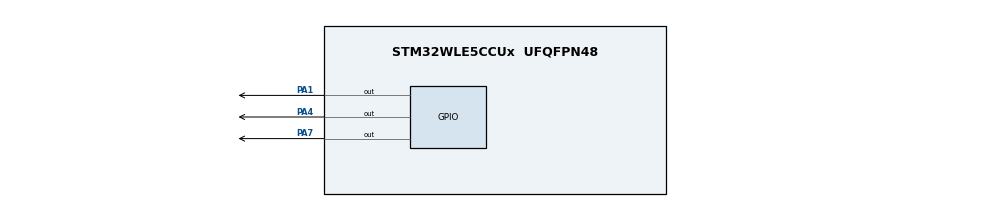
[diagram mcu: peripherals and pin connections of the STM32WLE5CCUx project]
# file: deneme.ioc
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ADC.Channel-0\#ChannelRegularConversion=ADC_CHANNEL_TEMPSENSOR
ADC.ContinuousConvMode=ENABLE
ADC.EnableRegularConversion=ENABLE
ADC.NbrOfConversion=1
ADC.NbrOfConversionFlag=1
ADC.Rank-0\#ChannelRegularConversion=1
ADC.SamplingTime-0\#ChannelRegularConversion=ADC_SAMPLINGTIME_COMMON_1
ADC.SamplingTimeCommon1=ADC_SAMPLETIME_79CYCLES_5
ADC.SelectedChannel=ADC_CHANNEL_TEMPSENSOR
Mcu.Family=STM32WL
Mcu.Name=STM32WLE5CCUx
Mcu.Package=UFQFPN48
NVIC.PriorityGroup=NVIC_PRIORITYGROUP_4
PA1.Signal=GPIO_Output
PA4.Signal=GPIO_Output
PA7.Signal=GPIO_Output
ProjectManager.HeapSize=0x200
ProjectManager.StackSize=0x400
ProjectManager.TargetToolchain=STM32CubeIDE
RCC.HSE_VALUE=8000000
RCC.HSI_VALUE=16000000
RCC.LSE_VALUE=32768
RCC.VCOOutputFreq_Value=32000000
VP_ADC_TempSens_Input.Mode=IN-TempSens
board=custom

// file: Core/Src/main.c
/* USER CODE BEGIN Header */
/**
  ******************************************************************************
  * @file           : main.c
  * @brief          : Main program body
  ******************************************************************************
  * @attention
  *
  * Copyright (c) 2022 STMicroelectronics.
  * All rights reserved.
  *
  * This software is licensed under terms that can be found in the LICENSE file
  * in the root directory of this software component.
  * If no LICENSE file comes with this software, it is provided AS-IS.
  *
  ******************************************************************************
  */
/* USER CODE END Header */
#include "main.h"

ADC_HandleTypeDef hadc;

/* USER CODE BEGIN PV */

uint16_t readValue;
float tCelsius;
float tFahrenheit;

/* USER CODE END PV */

void SystemClock_Config(void);
static void MX_GPIO_Init(void);
static void MX_ADC_Init(void);

int main(void)
{

  /* MCU Configuration--------------------------------------------------------*/

  /* Reset of all peripherals, Initializes the Flash interface and the Systick. */
  HAL_Init();

  /* Configure the system clock */
  SystemClock_Config();

  /* Initialize all configured peripherals */
  MX_GPIO_Init();
  MX_ADC_Init();
  /* USER CODE BEGIN 2 */
  HAL_ADC_Start(&hadc);

  /* USER CODE END 2 */

  /* Infinite loop */
  /* USER CODE BEGIN WHILE */
  while (1)
    {
      HAL_ADC_PollForConversion(&hadc,1000);
      readValue = HAL_ADC_GetValue(&hadc);
      tCelsius = 357.558 - 0.187364 * readValue;
      tFahrenheit = 675.6 - 0.337255 * readValue;
      if (readValue > 1740)
      {
        HAL_GPIO_WritePin(GPIOA, GPIO_PIN_7, 1);
        HAL_GPIO_WritePin(GPIOA, GPIO_PIN_4, 0);
        HAL_GPIO_WritePin(GPIOA, GPIO_PIN_1, 0);
      }
      else if (readValue > 1720 )
      {
        HAL_GPIO_WritePin(GPIOA, GPIO_PIN_7, 0);
        HAL_GPIO_WritePin(GPIOA, GPIO_PIN_4, 1);

        HAL_GPIO_WritePin(GPIOA, GPIO_PIN_1, 0);
      }
      else
      {
        HAL_GPIO_WritePin(GPIOA, GPIO_PIN_7, 0);
        HAL_GPIO_WritePin(GPIOA, GPIO_PIN_4, 0);
        HAL_GPIO_WritePin(GPIOA, GPIO_PIN_1, 1);
      }
      HAL_Delay(100);
    }
  /* USER CODE END 3 */
}

void SystemClock_Config(void)
{
  RCC_OscInitTypeDef RCC_OscInitStruct = {0};
  RCC_ClkInitTypeDef RCC_ClkInitStruct = {0};

  /** Configure the main internal regulator output voltage
  */
  __HAL_PWR_VOLTAGESCALING_CONFIG(PWR_REGULATOR_VOLTAGE_SCALE2);

  /** Initializes the CPU, AHB and APB buses clocks
  */
  RCC_OscInitStruct.OscillatorType = RCC_OSCILLATORTYPE_MSI;
  RCC_OscInitStruct.MSIState = RCC_MSI_ON;
  RCC_OscInitStruct.MSICalibrationValue = RCC_MSICALIBRATION_DEFAULT;
  RCC_OscInitStruct.MSIClockRange = RCC_MSIRANGE_6;
  RCC_OscInitStruct.PLL.PLLState = RCC_PLL_NONE;
  if (HAL_RCC_OscConfig(&RCC_OscInitStruct) != HAL_OK)
  {
    Error_Handler();
  }

  /** Configure the SYSCLKSource, HCLK, PCLK1 and PCLK2 clocks dividers
  */
  RCC_ClkInitStruct.ClockType = RCC_CLOCKTYPE_HCLK3|RCC_CLOCKTYPE_HCLK
                              |RCC_CLOCKTYPE_SYSCLK|RCC_CLOCKTYPE_PCLK1
                              |RCC_CLOCKTYPE_PCLK2;
  RCC_ClkInitStruct.SYSCLKSource = RCC_SYSCLKSOURCE_MSI;
  RCC_ClkInitStruct.AHBCLKDivider = RCC_SYSCLK_DIV1;
  RCC_ClkInitStruct.APB1CLKDivider = RCC_HCLK_DIV1;
  RCC_ClkInitStruct.APB2CLKDivider = RCC_HCLK_DIV1;
  RCC_ClkInitStruct.AHBCLK3Divider = RCC_SYSCLK_DIV1;

  if (HAL_RCC_ClockConfig(&RCC_ClkInitStruct, FLASH_LATENCY_0) != HAL_OK)
  {
    Error_Handler();
  }
}

static void MX_ADC_Init(void)
{

  ADC_ChannelConfTypeDef sConfig = {0};

  /** Configure the global features of the ADC (Clock, Resolution, Data Alignment and number of conversion)
  */
  hadc.Instance = ADC;
  hadc.Init.ClockPrescaler = ADC_CLOCK_SYNC_PCLK_DIV1;
  hadc.Init.Resolution = ADC_RESOLUTION_12B;
  hadc.Init.DataAlign = ADC_DATAALIGN_RIGHT;
  hadc.Init.ScanConvMode = ADC_SCAN_DISABLE;
  hadc.Init.EOCSelection = ADC_EOC_SINGLE_CONV;
  hadc.Init.LowPowerAutoWait = DISABLE;
  hadc.Init.LowPowerAutoPowerOff = DISABLE;
  hadc.Init.ContinuousConvMode = ENABLE;
  hadc.Init.NbrOfConversion = 1;
  hadc.Init.DiscontinuousConvMode = DISABLE;
  hadc.Init.ExternalTrigConv = ADC_SOFTWARE_START;
  hadc.Init.ExternalTrigConvEdge = ADC_EXTERNALTRIGCONVEDGE_NONE;
  hadc.Init.DMAContinuousRequests = DISABLE;
  hadc.Init.Overrun = ADC_OVR_DATA_PRESERVED;
  hadc.Init.SamplingTimeCommon1 = ADC_SAMPLETIME_79CYCLES_5;
  hadc.Init.SamplingTimeCommon2 = ADC_SAMPLETIME_1CYCLE_5;
  hadc.Init.OversamplingMode = DISABLE;
  hadc.Init.TriggerFrequencyMode = ADC_TRIGGER_FREQ_HIGH;
  if (HAL_ADC_Init(&hadc) != HAL_OK)
  {
    Error_Handler();
  }

  /** Configure Regular Channel
  */
  sConfig.Channel = ADC_CHANNEL_TEMPSENSOR;
  sConfig.Rank = ADC_REGULAR_RANK_1;
  sConfig.SamplingTime = ADC_SAMPLINGTIME_COMMON_1;
  if (HAL_ADC_ConfigChannel(&hadc, &sConfig) != HAL_OK)
  {
    Error_Handler();
  }

}

static void MX_GPIO_Init(void)
{
  GPIO_InitTypeDef GPIO_InitStruct = {0};

  /* GPIO Ports Clock Enable */
  __HAL_RCC_GPIOA_CLK_ENABLE();

  /*Configure GPIO pin Output Level */
  HAL_GPIO_WritePin(GPIOA, GPIO_PIN_1|GPIO_PIN_4|GPIO_PIN_7, GPIO_PIN_RESET);

  /*Configure GPIO pins : PA1 PA4 PA7 */
  GPIO_InitStruct.Pin = GPIO_PIN_1|GPIO_PIN_4|GPIO_PIN_7;
  GPIO_InitStruct.Mode = GPIO_MODE_OUTPUT_PP;
  GPIO_InitStruct.Pull = GPIO_NOPULL;
  GPIO_InitStruct.Speed = GPIO_SPEED_FREQ_LOW;
  HAL_GPIO_Init(GPIOA, &GPIO_InitStruct);

}

void Error_Handler(void)
{
  __disable_irq();
  while (1)
  {
  }
}
